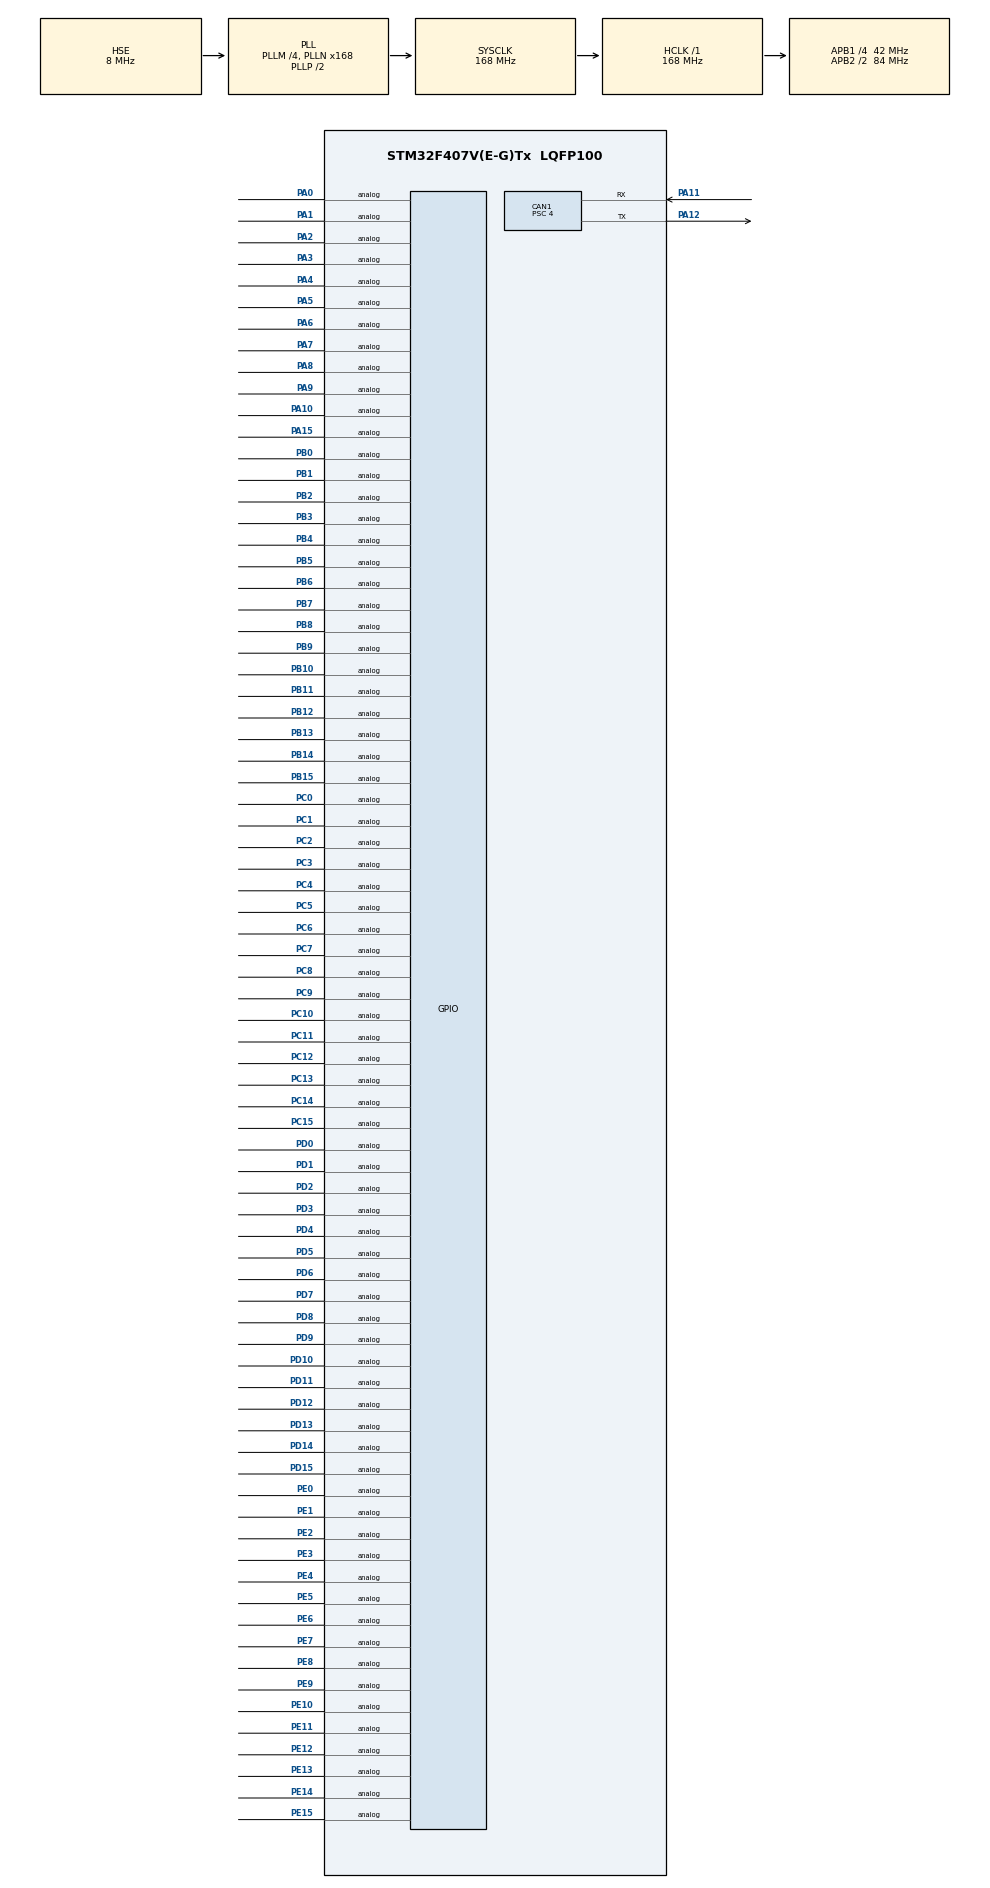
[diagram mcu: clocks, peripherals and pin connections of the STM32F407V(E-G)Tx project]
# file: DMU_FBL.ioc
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CAN1.ABOM=ENABLE
CAN1.AWUM=ENABLE
CAN1.BS1=CAN_BS1_16TQ
CAN1.BS2=CAN_BS2_4TQ
CAN1.CalculateBaudRate=500000
CAN1.CalculateTimeBit=2000
CAN1.CalculateTimeQuantum=95.23809523809524
CAN1.NART=ENABLE
CAN1.Prescaler=4
CAN1.RFLM=ENABLE
CAN1.SJW=CAN_SJW_1TQ
CAN1.TTCM=ENABLE
CAN1.TXFP=ENABLE
Mcu.Family=STM32F4
Mcu.Name=STM32F407V(E-G)Tx
Mcu.Package=LQFP100
NVIC.CAN1_RX0_IRQn=true\:0\:0\:false\:true\:true\:4\:true\:true\:true
NVIC.CAN1_TX_IRQn=true\:3\:0\:true\:true\:true\:5\:true\:true\:true
NVIC.FLASH_IRQn=true\:6\:0\:true\:true\:true\:2\:true\:true\:true
NVIC.FPU_IRQn=true\:4\:0\:true\:true\:true\:3\:true\:false\:true
NVIC.PVD_IRQn=true\:7\:0\:true\:true\:true\:1\:true\:true\:true
NVIC.PriorityGroup=NVIC_PRIORITYGROUP_4
NVIC.RCC_IRQn=true\:5\:0\:true\:true\:true\:6\:true\:false\:true
PA0-WKUP.Signal=GPIO_Analog
PA1.Signal=GPIO_Analog
PA10.Signal=GPIO_Analog
PA11.Mode=CAN_Activate
PA11.Signal=CAN1_RX
PA12.GPIO_PuPd=GPIO_PULLUP
PA12.Mode=CAN_Activate
PA12.Signal=CAN1_TX
PA13.Mode=Serial_Wire
PA13.Signal=SYS_JTMS-SWDIO
PA14.Mode=Serial_Wire
PA14.Signal=SYS_JTCK-SWCLK
PA15.Signal=GPIO_Analog
PA2.Signal=GPIO_Analog
PA3.Signal=GPIO_Analog
PA4.Signal=GPIO_Analog
PA5.Signal=GPIO_Analog
PA6.Signal=GPIO_Analog
PA7.Signal=GPIO_Analog
PA8.Signal=GPIO_Analog
PA9.Signal=GPIO_Analog
PB0.Signal=GPIO_Analog
PB1.Signal=GPIO_Analog
PB10.Signal=GPIO_Analog
PB11.Signal=GPIO_Analog
PB12.Signal=GPIO_Analog
PB13.Signal=GPIO_Analog
PB14.Signal=GPIO_Analog
PB15.Signal=GPIO_Analog
PB2.Signal=GPIO_Analog
PB3.Signal=GPIO_Analog
PB4.Signal=GPIO_Analog
PB5.Signal=GPIO_Analog
PB6.Signal=GPIO_Analog
PB7.Signal=GPIO_Analog
PB8.Signal=GPIO_Analog
PB9.Signal=GPIO_Analog
PC0.Signal=GPIO_Analog
PC1.Signal=GPIO_Analog
PC10.Signal=GPIO_Analog
PC11.Signal=GPIO_Analog
PC12.Signal=GPIO_Analog
PC13-ANTI_TAMP.Signal=GPIO_Analog
PC14-OSC32_IN.Signal=GPIO_Analog
PC15-OSC32_OUT.Signal=GPIO_Analog
PC2.Signal=GPIO_Analog
PC3.Signal=GPIO_Analog
PC4.Signal=GPIO_Analog
PC5.Signal=GPIO_Analog
PC6.Signal=GPIO_Analog
PC7.Signal=GPIO_Analog
PC8.Signal=GPIO_Analog
PC9.Signal=GPIO_Analog
PD0.Signal=GPIO_Analog
PD1.Signal=GPIO_Analog
PD10.Signal=GPIO_Analog
PD11.Signal=GPIO_Analog
PD12.Signal=GPIO_Analog
PD13.Signal=GPIO_Analog
PD14.Signal=GPIO_Analog
PD15.Signal=GPIO_Analog
PD2.Signal=GPIO_Analog
PD3.Signal=GPIO_Analog
PD4.Signal=GPIO_Analog
PD5.Signal=GPIO_Analog
PD6.Signal=GPIO_Analog
PD7.Signal=GPIO_Analog
PD8.Signal=GPIO_Analog
PD9.Signal=GPIO_Analog
PE0.Signal=GPIO_Analog
PE1.Signal=GPIO_Analog
PE10.Signal=GPIO_Analog
PE11.Signal=GPIO_Analog
PE12.Signal=GPIO_Analog
PE13.Signal=GPIO_Analog
PE14.Signal=GPIO_Analog
PE15.Signal=GPIO_Analog
PE2.Signal=GPIO_Analog
PE3.Signal=GPIO_Analog
PE4.Signal=GPIO_Analog
PE5.Signal=GPIO_Analog
PE6.Signal=GPIO_Analog
PE7.Signal=GPIO_Analog
PE8.Signal=GPIO_Analog
PE9.Signal=GPIO_Analog
PH0-OSC_IN.Mode=HSE-External-Oscillator
PH0-OSC_IN.Signal=RCC_OSC_IN
PH1-OSC_OUT.Mode=HSE-External-Oscillator
PH1-OSC_OUT.Signal=RCC_OSC_OUT
ProjectManager.HeapSize=0x200
ProjectManager.StackSize=0x200
ProjectManager.TargetToolchain=STM32CubeIDE
RCC.48MHZClocksFreq_Value=84000000
RCC.AHBFreq_Value=168000000
RCC.APB1CLKDivider=RCC_HCLK_DIV4
RCC.APB1Freq_Value=42000000
RCC.APB1TimFreq_Value=84000000
RCC.APB2CLKDivider=RCC_HCLK_DIV2
RCC.APB2Freq_Value=84000000
RCC.APB2TimFreq_Value=168000000
RCC.CortexFreq_Value=168000000
RCC.HCLKFreq_Value=168000000
RCC.HSE_VALUE=8000000
RCC.HSI_VALUE=16000000
RCC.LSE_VALUE=32768
RCC.PLLM=4
RCC.PLLN=168
RCC.PLLSourceVirtual=RCC_PLLSOURCE_HSE
RCC.RCC_MCO1Source=RCC_MCO1SOURCE_PLLCLK
RCC.RCC_MCODiv1=RCC_MCODIV_4
RCC.SYSCLKFreq_VALUE=168000000
RCC.SYSCLKSource=RCC_SYSCLKSOURCE_PLLCLK
RCC.VCOOutputFreq_Value=336000000
RCC.VDD_VALUE=3.6
board=custom

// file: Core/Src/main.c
/* USER CODE BEGIN Header */
/* USER CODE END Header */
#include "main.h"
#include "can.h"
#include "gpio.h"

/* USER CODE BEGIN Includes */
#include <string.h>
#include <stdbool.h>
/* USER CODE END Includes */

/* USER CODE BEGIN PTD */
typedef uint8_t uint8;
typedef uint16_t uint16;
typedef uint32_t uint32;
typedef enum
{
	DEFAULT = 0U,
	EXTENDED = 1U,
	PROGRAMMING = 2U,
	HARDRESET = 5U,
	SOFTRESET = 6U,
	JUMPTOAPPL = 7U
}FBL_DSC_t;
/* USER CODE END PTD */

/* USER CODE BEGIN PD */
#define SESSIONSTATUS_ADDR 					0x1000fc00
#define NCR_START_ADDRESS 					0x1000f000
#define NCR_END_ADDRESS   					0x1000fffe
#define NCR_SIZE          					(NCR_END_ADDRESS - NCR_START_ADDRESS + 1)
#define APPL_START_ADDRESS 					0x08020000
#define RESET_COUNTER_ADDRESS				0x1000fc70
/* USER CODE END PD */

/* USER CODE BEGIN PV */
uint8 FBL_RxFrame[8] = {0};
uint8 FBL_TxFrame[8] = {0};
CAN_RxHeaderTypeDef FBL_RxHeader = {0, 0, 0, 0, 0, 0, 0};
CAN_TxHeaderTypeDef FBL_TxHeader = {0, 0, 0, 0, 0, 0};
uint32 FBL_TxMailbox = 0;
uint32* FBL_DSC_Pointer = (uint32*)(SESSIONSTATUS_ADDR);
FBL_DSC_t FBL_DSC_State = JUMPTOAPPL;
uint32* FBL_ResetCounterFBL = (uint32*)(RESET_COUNTER_ADDRESS);
uint32 FBL_ProgrammingData = 0;
uint32 FBL_ProgrammingIndex = 0;
uint32 FBL_ProgrammingAddress = 0;
uint32 ROM_APPL_START_ADDR_storedValue = 0;
uint32 ROM_APPL_START_ADDR = 0x08020000;
uint32 FBL_DSC_Status = 0;
/* USER CODE END PV */

void SystemClock_Config(void);
static void MX_NVIC_Init(void);
/* USER CODE BEGIN PFP */
void FBL_JumpToAppl(void);
void FBL_DiagService_ER_SoftReset(void);
void FBL_DiagService_ER_HardReset(void);
void FBL_DiagService_DSC_Programming(void);
void FBL_DiagService_DSC_RequestDownload(void);
void FBL_DiagService_DSC_TransferData(void);
void FBL_DiagService_DSC_RequestTransferExit(void);
void FBL_DiagService_RAR_MassEraseAPPL(void);
void FBL_DiagService_RDBI_ReadActiveDiagnosticSession(void);
void FBL_NvM_FlashReadData(uint32 StartSectorAddress, uint32 *RxBuf, uint16 numberofwords);
uint32 FBL_NvM_FlashWriteData(uint32 StartSectorAddress, uint32 *Data, uint16 numberofwords);
uint32 FBL_NvM_EraseFlash_APPL(void);
uint32 FBL_NvM_GetSector(uint32 Address);
/* USER CODE END PFP */

/* USER CODE BEGIN 0 */
void HAL_CAN_RxFifo0FullCallback(CAN_HandleTypeDef *hcan)
{
	HAL_CAN_GetRxMessage(&hcan1, CAN_RX_FIFO0, &FBL_RxHeader, FBL_RxFrame);
	switch(FBL_DSC_State)
	{
	case PROGRAMMING:
		FBL_DiagService_DSC_Programming();
		break;
	case HARDRESET:
		FBL_DiagService_ER_HardReset();
		break;
	case SOFTRESET:
		FBL_DiagService_ER_SoftReset();
		break;
	default:
		if(FBL_RxFrame[1] == 0x50 && FBL_RxFrame[2] == 0x02)
		{
			FBL_TxHeader.DLC = FBL_RxHeader.DLC;
			FBL_TxHeader.StdId = FBL_RxHeader.StdId + 1;
			FBL_TxFrame[0] = FBL_RxFrame[0];
			FBL_TxFrame[1] = FBL_RxFrame[1] + 0x40;
			FBL_TxFrame[2] = FBL_RxFrame[2];
			FBL_DSC_State = PROGRAMMING;
			HAL_CAN_AddTxMessage(&hcan1, &FBL_TxHeader, FBL_TxFrame, &FBL_TxMailbox);
			FBL_DiagService_DSC_Programming();
		}
		else
		{
			/* Do nothing. */
		}
		break;
	}
}
void HAL_CAN_RxFifo0MsgPendingCallback(CAN_HandleTypeDef *hcan)
{
	HAL_CAN_GetRxMessage(&hcan1, CAN_RX_FIFO0, &FBL_RxHeader, FBL_RxFrame);
	switch(FBL_DSC_State)
	{
	case PROGRAMMING:
		FBL_DiagService_DSC_Programming();
		break;
	case HARDRESET:
		FBL_DiagService_ER_HardReset();
		break;
	case SOFTRESET:
		FBL_DiagService_ER_SoftReset();
		break;
	default:
		if(FBL_RxFrame[1] == 0x10 && FBL_RxFrame[2] == 0x02)
		{
			FBL_TxHeader.DLC = FBL_RxHeader.DLC;
			FBL_TxHeader.StdId = FBL_RxHeader.StdId + 1;
			FBL_TxFrame[0] = FBL_RxFrame[0];
			FBL_TxFrame[1] = FBL_RxFrame[1] + 0x40;
			FBL_TxFrame[2] = FBL_RxFrame[2];
			FBL_DSC_State = PROGRAMMING;
			HAL_CAN_AddTxMessage(&hcan1, &FBL_TxHeader, FBL_TxFrame, &FBL_TxMailbox);
			FBL_DiagService_DSC_Programming();
		}
		else
		{
			/* Do nothing. */
		}
		break;
	}
}
/* USER CODE END 0 */

int main(void)
{

	/* MCU Configuration--------------------------------------------------------*/

	/* Reset of all peripherals, Initializes the Flash interface and the Systick. */
	HAL_Init();

	/* Configure the system clock */
	SystemClock_Config();

	/* Initialize all configured peripherals */
	MX_GPIO_Init();
	MX_CAN1_Init();

	/* Initialize interrupts */
	MX_NVIC_Init();
	/* USER CODE BEGIN 2 */

	if((RCC->CSR & RCC_CSR_PORRSTF) != 0)
	{
		for(uint32* addr = ((uint32*)NCR_START_ADDRESS); addr <= ((uint32*)NCR_END_ADDRESS); addr++) *addr = 0;
		/* Reset the flag. */
		RCC->CSR |= RCC_CSR_PORRSTF;
		RCC->CSR |= RCC_CSR_RMVF;
	}/* Check if brown-out reset wake-up event occurred.*/
	else if((RCC->CSR & RCC_CSR_BORRSTF) != 0)
	{
		for(uint32* addr = ((uint32*)NCR_START_ADDRESS); addr <= ((uint32*)NCR_END_ADDRESS); addr++) *addr = 0;
		/* Reset the flag. */
		RCC->CSR |= RCC_CSR_BORRSTF;
		RCC->CSR |= RCC_CSR_RMVF;
	}
	else
	{
		/* Do nothing. */
	}

	if(*FBL_ResetCounterFBL == 50)
	{
		FBL_DSC_Status = PROGRAMMING;
	}
	else
	{
		/* Do nothing. */
	}

	FBL_ProgrammingAddress = 0;
	FBL_ProgrammingIndex = 0;

	if(*FBL_ResetCounterFBL == 50)
	{
		FBL_DSC_Status = PROGRAMMING;
	}
	else
	{
		FBL_NvM_FlashReadData(ROM_APPL_START_ADDR, &ROM_APPL_START_ADDR_storedValue, 1);

		if(ROM_APPL_START_ADDR_storedValue != 0xFFFFFFFF)
		{
			FBL_DSC_Pointer = (uint32*)(SESSIONSTATUS_ADDR);
			FBL_DSC_Status = *FBL_DSC_Pointer;
		}
		else
		{
			/* Do nothing. */
		}
	}

	if((FBL_DSC_Status == PROGRAMMING) || (FBL_DSC_Status == SOFTRESET) || (FBL_DSC_Status == HARDRESET))
	{
		FBL_DSC_State = FBL_DSC_Status;
		if(FBL_DSC_Status == SOFTRESET) FBL_DiagService_ER_SoftReset();
		else if(FBL_DSC_Status == HARDRESET) FBL_DiagService_ER_HardReset();
		else
		{
			/* Do nothing. */
		}
	}
	else
	{
		if(ROM_APPL_START_ADDR_storedValue != 0xFFFFFFFF)
		{
			FBL_JumpToAppl();
		}
		else
		{
			/* Do nothing. */
		}
	}
	/* USER CODE END 2 */

	/* Infinite loop */
	while (1){}

}

void SystemClock_Config(void)
{
	RCC_OscInitTypeDef RCC_OscInitStruct = {0};
	RCC_ClkInitTypeDef RCC_ClkInitStruct = {0};

	/** Configure the main internal regulator output voltage
	 */
	__HAL_RCC_PWR_CLK_ENABLE();
	__HAL_PWR_VOLTAGESCALING_CONFIG(PWR_REGULATOR_VOLTAGE_SCALE1);

	/** Initializes the RCC Oscillators according to the specified parameters
	 * in the RCC_OscInitTypeDef structure.
	 */
	RCC_OscInitStruct.OscillatorType = RCC_OSCILLATORTYPE_HSE;
	RCC_OscInitStruct.HSEState = RCC_HSE_ON;
	RCC_OscInitStruct.PLL.PLLState = RCC_PLL_ON;
	RCC_OscInitStruct.PLL.PLLSource = RCC_PLLSOURCE_HSE;
	RCC_OscInitStruct.PLL.PLLM = 4;
	RCC_OscInitStruct.PLL.PLLN = 168;
	RCC_OscInitStruct.PLL.PLLP = RCC_PLLP_DIV2;
	RCC_OscInitStruct.PLL.PLLQ = 4;
	if (HAL_RCC_OscConfig(&RCC_OscInitStruct) != HAL_OK)
	{
		Error_Handler();
	}

	/** Initializes the CPU, AHB and APB buses clocks
	 */
	RCC_ClkInitStruct.ClockType = RCC_CLOCKTYPE_HCLK|RCC_CLOCKTYPE_SYSCLK
			|RCC_CLOCKTYPE_PCLK1|RCC_CLOCKTYPE_PCLK2;
	RCC_ClkInitStruct.SYSCLKSource = RCC_SYSCLKSOURCE_PLLCLK;
	RCC_ClkInitStruct.AHBCLKDivider = RCC_SYSCLK_DIV1;
	RCC_ClkInitStruct.APB1CLKDivider = RCC_HCLK_DIV4;
	RCC_ClkInitStruct.APB2CLKDivider = RCC_HCLK_DIV2;

	if (HAL_RCC_ClockConfig(&RCC_ClkInitStruct, FLASH_LATENCY_5) != HAL_OK)
	{
		Error_Handler();
	}
}

/**
 * @brief NVIC Configuration.
 * @retval None
 */
static void MX_NVIC_Init(void)
{
	/* PVD_IRQn interrupt configuration */
	HAL_NVIC_SetPriority(PVD_IRQn, 7, 0);
	HAL_NVIC_EnableIRQ(PVD_IRQn);
	/* FLASH_IRQn interrupt configuration */
	HAL_NVIC_SetPriority(FLASH_IRQn, 6, 0);
	HAL_NVIC_EnableIRQ(FLASH_IRQn);
	/* FPU_IRQn interrupt configuration */
	HAL_NVIC_SetPriority(FPU_IRQn, 4, 0);
	HAL_NVIC_EnableIRQ(FPU_IRQn);
	/* CAN1_RX0_IRQn interrupt configuration */
	HAL_NVIC_SetPriority(CAN1_RX0_IRQn, 0, 0);
	HAL_NVIC_EnableIRQ(CAN1_RX0_IRQn);
	/* CAN1_TX_IRQn interrupt configuration */
	HAL_NVIC_SetPriority(CAN1_TX_IRQn, 3, 0);
	HAL_NVIC_EnableIRQ(CAN1_TX_IRQn);
	/* RCC_IRQn interrupt configuration */
	HAL_NVIC_SetPriority(RCC_IRQn, 5, 0);
	HAL_NVIC_EnableIRQ(RCC_IRQn);
}

/* USER CODE BEGIN 4 */
uint32 FBL_NvM_GetSector(uint32 Address)
{
	uint32 sector = 0;
	if((Address < 0x08003FFF) && (Address >= 0x08000000)) sector = FLASH_SECTOR_0;
	else if((Address < 0x08007FFF) && (Address >= 0x08004000)) sector = FLASH_SECTOR_1;
	else if((Address < 0x0800BFFF) && (Address >= 0x08008000)) sector = FLASH_SECTOR_2;
	else if((Address <= 0x0800FFFF) && (Address >= 0x0800C000)) sector = FLASH_SECTOR_3;
	else if((Address <= 0x0801FFFF) && (Address >= 0x08010000)) sector = FLASH_SECTOR_4;
	else if((Address < 0x0803FFFF) && (Address >= 0x08020000)) sector = FLASH_SECTOR_5;
	else if((Address < 0x0805FFFF) && (Address >= 0x08040000)) sector = FLASH_SECTOR_6;
	else if((Address < 0x0807FFFF) && (Address >= 0x08060000)) sector = FLASH_SECTOR_7;
	else
	{
		/* Do nothing. */
	}
	return sector;
}
uint32 FBL_NvM_EraseFlash_APPL(void)
{
	FLASH_EraseInitTypeDef EraseInitStruct = {0};
	uint32 SECTORError = 0;
	uint32 StartSector = 0;
	uint32 EndSector = 0;
	StartSector = FLASH_SECTOR_5;
	EndSector = FLASH_SECTOR_7;
	HAL_FLASH_Unlock();
	EraseInitStruct.TypeErase     = FLASH_TYPEERASE_SECTORS;
	EraseInitStruct.VoltageRange  = FLASH_VOLTAGE_RANGE_3;
	EraseInitStruct.Sector        = StartSector;
	EraseInitStruct.NbSectors     = (EndSector - StartSector) + 1;
	if (HAL_FLASHEx_Erase(&EraseInitStruct, &SECTORError) != HAL_OK) return HAL_FLASH_GetError();
	else
	{
		/* Do nothing. */
	}
	HAL_FLASH_Lock();
	return 0;
}
uint32 FBL_NvM_FlashWriteData(uint32 StartSectorAddress, uint32 *Data, uint16 numberofwords)
{
	uint32 sofar = 0;
	HAL_FLASH_Unlock();
	while(sofar < numberofwords)
	{
		if(HAL_FLASH_Program(FLASH_TYPEPROGRAM_WORD, StartSectorAddress, Data[sofar]) == HAL_OK)
		{
			StartSectorAddress += 4;
			sofar++;
		}
		else return HAL_FLASH_GetError ();
	}
	HAL_FLASH_Lock();
	return 0;
}
void FBL_NvM_FlashReadData(uint32 StartSectorAddress, uint32 *RxBuf, uint16 numberofwords)
{
	for (uint16 i = 0; i < numberofwords; i++) 	RxBuf[i] = *(__IO uint32 *)(StartSectorAddress + (i * 4));
}
void FBL_DiagService_DSC_RequestDownload(void)
{
	FBL_TxHeader.DLC = FBL_RxHeader.DLC;
	FBL_TxHeader.StdId = FBL_RxHeader.StdId + 1;
	FBL_TxFrame[0] = FBL_RxFrame[0];
	FBL_TxFrame[1] = FBL_RxFrame[1] + 0x40;
	FBL_TxFrame[2] = FBL_RxFrame[2];
	FBL_DSC_State = PROGRAMMING;
	HAL_CAN_AddTxMessage(&hcan1, &FBL_TxHeader, FBL_TxFrame, &FBL_TxMailbox);
	for(uint8 i = 0; i < 8 ; i++) FBL_TxFrame[i] = 0;
	FBL_TxHeader.DLC = 0;
	FBL_TxHeader.ExtId = 0;
	FBL_TxHeader.IDE = 0;
	FBL_TxHeader.RTR = 0;
	FBL_TxHeader.StdId = 0;
	FBL_TxHeader.TransmitGlobalTime = 0;
	FBL_TxMailbox = 0;
}
void FBL_DiagService_DSC_TransferData(void)
{
	FBL_ProgrammingData = (FBL_RxFrame[6] << 24) | (FBL_RxFrame[5] << 16) | (FBL_RxFrame[4] << 8) | FBL_RxFrame[3];
	__disable_irq();
	FBL_NvM_FlashWriteData(FBL_ProgrammingAddress, &FBL_ProgrammingData, 1);
	__enable_irq();
	FBL_ProgrammingAddress += 4;
	FBL_ProgrammingIndex += 1;
	FBL_TxHeader.DLC = FBL_RxHeader.DLC;
	FBL_TxHeader.StdId = FBL_RxHeader.StdId + 1;
	FBL_TxFrame[0] = FBL_RxFrame[0];
	FBL_TxFrame[1] = FBL_RxFrame[1] + 0x40;
	FBL_TxFrame[2] = FBL_RxFrame[2];
	HAL_CAN_AddTxMessage(&hcan1, &FBL_TxHeader, FBL_TxFrame, &FBL_TxMailbox);
	for(uint8 i = 0; i < 8 ; i++) FBL_TxFrame[i] = 0;
	FBL_TxHeader.DLC = 0;
	FBL_TxHeader.ExtId = 0;
	FBL_TxHeader.IDE = 0;
	FBL_TxHeader.RTR = 0;
	FBL_TxHeader.StdId = 0;
	FBL_TxHeader.TransmitGlobalTime = 0;
	FBL_TxMailbox = 0;
}
void FBL_DiagService_DSC_RequestTransferExit(void)
{
	FBL_TxHeader.DLC = FBL_RxHeader.DLC;
	FBL_TxHeader.StdId = FBL_RxHeader.StdId + 1;
	FBL_TxFrame[0] = FBL_RxFrame[0];
	FBL_TxFrame[1] = FBL_RxFrame[1] + 0x40;
	FBL_TxFrame[2] = FBL_RxFrame[2];
	HAL_CAN_AddTxMessage(&hcan1, &FBL_TxHeader, FBL_TxFrame, &FBL_TxMailbox);
	for(uint8 i = 0; i < 8 ; i++) FBL_TxFrame[i] = 0;
	FBL_TxHeader.DLC = 0;
	FBL_TxHeader.ExtId = 0;
	FBL_TxHeader.IDE = 0;
	FBL_TxHeader.RTR = 0;
	FBL_TxHeader.StdId = 0;
	FBL_TxHeader.TransmitGlobalTime = 0;
	FBL_TxMailbox = 0;
}
void FBL_DiagService_RAR_MassEraseAPPL(void)
{
	__disable_irq();
	FBL_TxHeader.DLC = FBL_RxHeader.DLC;
	FBL_TxHeader.StdId = FBL_RxHeader.StdId + 1;
	FBL_TxFrame[0] = FBL_RxFrame[0];
	FBL_TxFrame[1] = FBL_RxFrame[1] + 0x40;
	FBL_TxFrame[2] = FBL_RxFrame[2];
	HAL_CAN_AddTxMessage(&hcan1, &FBL_TxHeader, FBL_TxFrame, &FBL_TxMailbox);
	FBL_NvM_EraseFlash_APPL();
	for(uint8 i = 0; i < 8 ; i++) FBL_TxFrame[i] = 0;
	FBL_TxHeader.DLC = 0;
	FBL_TxHeader.ExtId = 0;
	FBL_TxHeader.IDE = 0;
	FBL_TxHeader.RTR = 0;
	FBL_TxHeader.StdId = 0;
	FBL_TxHeader.TransmitGlobalTime = 0;
	FBL_TxMailbox = 0;
	__enable_irq();
}
void FBL_JumpToAppl(void)
{
	typedef void (*pFunction)(void);
	static uint32 app_address = APPL_START_ADDRESS;
	static pFunction app_entry;
	uint32 msp_value = *((uint32*)app_address);
	__disable_irq();
	SCB->VTOR = app_address;
	__set_MSP(msp_value);
	app_entry = (pFunction)(*((uint32*)(app_address + 4)));
	app_entry();
}
void FBL_DiagService_ER_SoftReset(void)
{
	__disable_irq();
	*FBL_DSC_Pointer = 0;
	__NVIC_SystemReset();
}
void FBL_DiagService_ER_HardReset(void)
{
	__disable_irq();
	*FBL_DSC_Pointer = 0;
	for(uint32* addr = ((uint32*)NCR_START_ADDRESS); addr <= ((uint32*)NCR_END_ADDRESS); addr++) *addr = 0;
	__NVIC_SystemReset();
}

void FBL_DiagService_RDBI_ReadActiveDiagnosticSession(void)
{
	FBL_TxHeader.DLC = FBL_RxHeader.DLC + 1;
	FBL_TxHeader.StdId = FBL_RxHeader.StdId + 1;
	FBL_TxFrame[0] = FBL_RxFrame[0] + 1;
	FBL_TxFrame[1] = FBL_RxFrame[1] + 0x40;
	FBL_TxFrame[2] = FBL_RxFrame[2];
	FBL_TxFrame[3] = FBL_RxFrame[3];
	FBL_TxFrame[4] = FBL_DSC_State;
	HAL_CAN_AddTxMessage(&hcan1, &FBL_TxHeader, FBL_TxFrame, &FBL_TxMailbox);
	for(uint8 i = 0; i < 8 ; i++) FBL_TxFrame[i] = 0;
	FBL_TxHeader.DLC = 0;
	FBL_TxHeader.ExtId = 0;
	FBL_TxHeader.IDE = 0;
	FBL_TxHeader.RTR = 0;
	FBL_TxHeader.StdId = 0;
	FBL_TxHeader.TransmitGlobalTime = 0;
	FBL_TxMailbox = 0;
}
void FBL_DiagService_DSC_Programming(void)
{
	if(FBL_RxFrame[1] == 0x22 && FBL_RxFrame[2] == 0xF1 && FBL_RxFrame[3] == 0x86) FBL_DiagService_RDBI_ReadActiveDiagnosticSession();
	else
	{
		/* Do nothing. */
	}
	if(FBL_RxFrame[0] == 0x04 && FBL_RxFrame[1] == 0x31 && FBL_RxFrame[4] == 0x00) FBL_DiagService_RAR_MassEraseAPPL();
	else
	{
		/* Do nothing. */
	}
	if(FBL_RxFrame[1] == 0x34)
	{
		FBL_ProgrammingAddress = (0x08 << 24)
												| (FBL_RxFrame[4] << 16)
												| (FBL_RxFrame[5] << 8)
												| (FBL_RxFrame[6]);
		FBL_DiagService_DSC_RequestDownload();
	}
	else
	{
		/* Do nothing. */
	}
	if(FBL_RxFrame[1] == 0x36) FBL_DiagService_DSC_TransferData();
	if(FBL_RxFrame[1] == 0x37 && FBL_RxFrame[0] == 0x01) FBL_DiagService_DSC_RequestTransferExit();
	else
	{
		/* Do nothing. */
	}
	if(FBL_RxFrame[1] == 0x11 && FBL_RxFrame[2] == 0x01)
	{
		FBL_TxHeader.DLC = FBL_RxHeader.DLC;
		FBL_TxHeader.StdId = FBL_RxHeader.StdId + 1;
		FBL_TxFrame[0] = FBL_RxFrame[0];
		FBL_TxFrame[1] = FBL_RxFrame[1] + 0x40;
		FBL_TxFrame[2] = FBL_RxFrame[2];
		FBL_TxFrame[3] = FBL_RxFrame[3];
		HAL_CAN_AddTxMessage(&hcan1, &FBL_TxHeader, FBL_TxFrame, &FBL_TxMailbox);
		for(uint32 i = 0; i < 200000; i ++);
		FBL_DiagService_ER_HardReset();
	}
	else
	{
		/* Do nothing. */
	}
}
/* USER CODE END 4 */

void Error_Handler(void)
{
	/* USER CODE BEGIN Error_Handler_Debug */
	__disable_irq();
	__NVIC_SystemReset();
	(*FBL_ResetCounterFBL)++;
	/* USER CODE END Error_Handler_Debug */
}
